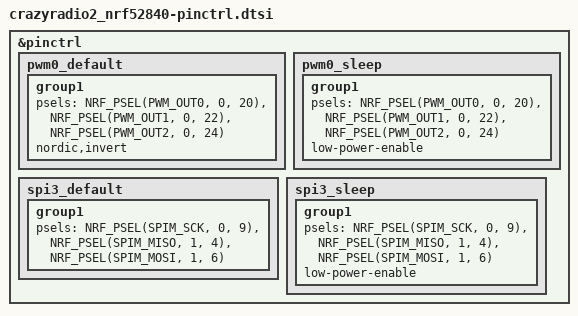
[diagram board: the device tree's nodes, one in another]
/*
 * Copyright (c) 2025 Bitcraze AB
 *
 * SPDX-License-Identifier: Apache-2.0
 */

&pinctrl {
	pwm0_default: pwm0_default {
		group1 {
			psels = <NRF_PSEL(PWM_OUT0, 0, 20)>,
				<NRF_PSEL(PWM_OUT1, 0, 22)>,
				<NRF_PSEL(PWM_OUT2, 0, 24)>;
			nordic,invert;
		};
	};

	pwm0_sleep: pwm0_sleep {
		group1 {
			psels = <NRF_PSEL(PWM_OUT0, 0, 20)>,
				<NRF_PSEL(PWM_OUT1, 0, 22)>,
				<NRF_PSEL(PWM_OUT2, 0, 24)>;
			low-power-enable;
		};
	};

	spi3_default: spi3_default {
		group1 {
			psels = <NRF_PSEL(SPIM_SCK, 0, 9)>,
				<NRF_PSEL(SPIM_MISO, 1, 4)>,
				<NRF_PSEL(SPIM_MOSI, 1, 6)>;
		};
	};

	spi3_sleep: spi3_sleep {
		group1 {
			psels = <NRF_PSEL(SPIM_SCK, 0, 9)>,
				<NRF_PSEL(SPIM_MISO, 1, 4)>,
				<NRF_PSEL(SPIM_MOSI, 1, 6)>;
			low-power-enable;
		};
	};
};
